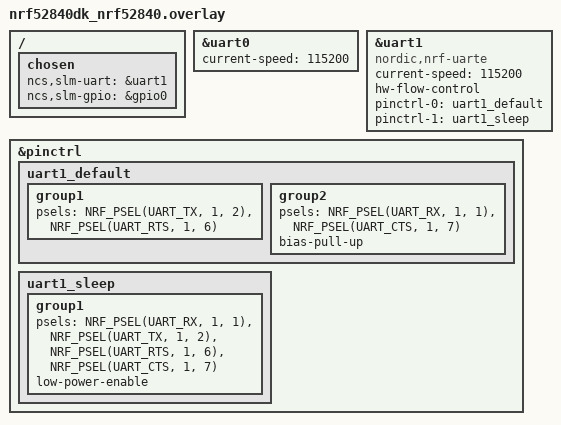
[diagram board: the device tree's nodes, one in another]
/*
 * Copyright (c) 2023 Nordic Semiconductor ASA
 *
 * SPDX-License-Identifier: LicenseRef-Nordic-5-Clause
 */

/ {
	chosen {
		ncs,slm-uart = &uart1;
		ncs,slm-gpio = &gpio0;
	};
};

/* Shell UART */
&uart0 {
	current-speed = <115200>;
	status = "okay";
};

/* SLM Shell <-> SLM UART */
&uart1 {
	compatible = "nordic,nrf-uarte";
	current-speed = <115200>;
	status = "okay";
	hw-flow-control;

	pinctrl-0 = <&uart1_default>;
	pinctrl-1 = <&uart1_sleep>;
	pinctrl-names = "default", "sleep";
};

&pinctrl {
	uart1_default: uart1_default {
		group1 {
			psels = <NRF_PSEL(UART_TX, 1, 2)>,
				<NRF_PSEL(UART_RTS, 1, 6)>;
		};
		group2 {
			psels = <NRF_PSEL(UART_RX, 1, 1)>,
				<NRF_PSEL(UART_CTS, 1, 7)>;
			bias-pull-up;
		};
	};

	uart1_sleep: uart1_sleep {
		group1 {
			psels = <NRF_PSEL(UART_RX, 1, 1)>,
				<NRF_PSEL(UART_TX, 1, 2)>,
				<NRF_PSEL(UART_RTS, 1, 6)>,
				<NRF_PSEL(UART_CTS, 1, 7)>;
			low-power-enable;
		};
	};
};
